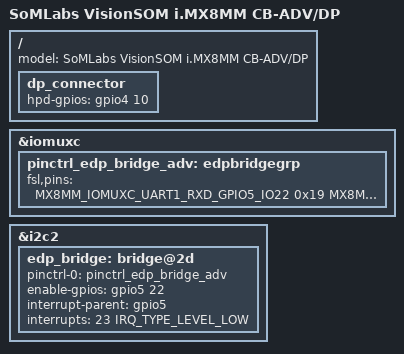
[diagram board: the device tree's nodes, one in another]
// SPDX-License-Identifier: GPL-2.0-or-later
/*
 * Copyright 2025 SomLabs
 *
 */

/dts-v1/;

#include "visionsom-8mm-cb-adv.dts"
#include "visionsom-8mm-cb-dp.dtsi"

/ {
    model = "SoMLabs VisionSOM i.MX8MM CB-ADV/DP";

    dp_connector {
        hpd-gpios = <&gpio4 10 GPIO_ACTIVE_HIGH>;
    };
};

&iomuxc {
    pinctrl_edp_bridge_adv: edpbridgegrp {
        fsl,pins = <
            MX8MM_IOMUXC_UART1_RXD_GPIO5_IO22               0x19    /* ENABLE */
            MX8MM_IOMUXC_UART1_TXD_GPIO5_IO23               0x81    /* interrupt */
            MX8MM_IOMUXC_SAI1_TXFS_GPIO4_IO10               0x81    /* HPD */
        >;
    };
};

&i2c2 {

    /* MIPI-DSI to HDMI adapter */
    edp_bridge: bridge@2d {
        pinctrl-0 = <&pinctrl_edp_bridge_adv>;
        enable-gpios = <&gpio5 22 GPIO_ACTIVE_HIGH>;
        interrupt-parent = <&gpio5>;
        interrupts = <23 IRQ_TYPE_LEVEL_LOW>;
    };
};
